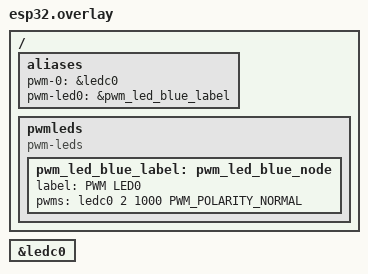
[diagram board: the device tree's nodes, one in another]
/*
 * SPDX-License-Identifier: Apache-2.0
 *
 * Copyright (c) 2021 Andrei-Edward Popa
 */

/* zephyrproject/zephyr/include/dt-bindings/pwm/pwm.h */
#include <dt-bindings/pwm/pwm.h>

/ {
	aliases {
    /* should include only characters from [0-9a-z-] */
		pwm-0 = &ledc0;
		pwm-led0 = &pwm_led_blue_label;
	};

	pwmleds {
		compatible = "pwm-leds";
		pwm_led_blue_label: pwm_led_blue_node {
		   label = "PWM LED0";
		   pwms = <&ledc0 2 1000 PWM_POLARITY_NORMAL>;
		};
	};
};

&ledc0 {
	status = "okay";
};
